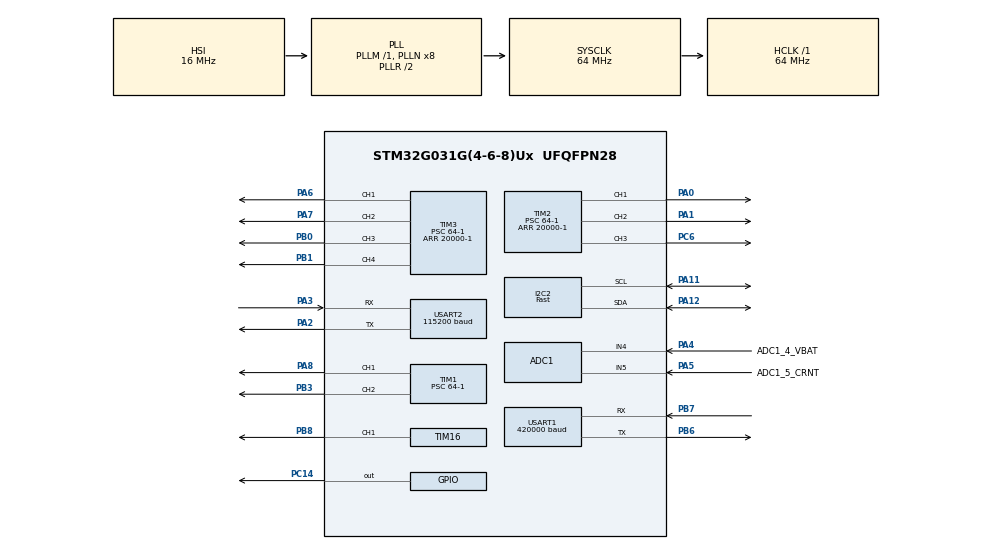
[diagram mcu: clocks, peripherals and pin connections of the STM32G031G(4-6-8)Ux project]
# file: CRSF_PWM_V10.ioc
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ADC1.Channel-4\#ChannelRegularConversion=ADC_CHANNEL_4
ADC1.Channel-5\#ChannelRegularConversion=ADC_CHANNEL_5
ADC1.ClockPrescaler=ADC_CLOCK_ASYNC_DIV128
ADC1.ContinuousConvMode=ENABLE
ADC1.DMAContinuousRequests=ENABLE
ADC1.DiscontinuousConvMode=DISABLE
ADC1.EOCSelection=ADC_EOC_SEQ_CONV
ADC1.LowPowerAutoPowerOff=DISABLE
ADC1.NbrOfConversion=2
ADC1.NbrOfConversionFlag=1
ADC1.Overrun=ADC_OVR_DATA_PRESERVED
ADC1.OversamplingMode=ENABLE
ADC1.Rank-4\#ChannelRegularConversion=1
ADC1.Rank-5\#ChannelRegularConversion=2
ADC1.Ratio=ADC_OVERSAMPLING_RATIO_16
ADC1.SamplingTime-4\#ChannelRegularConversion=ADC_SAMPLINGTIME_COMMON_1
ADC1.SamplingTime-5\#ChannelRegularConversion=ADC_SAMPLINGTIME_COMMON_1
ADC1.SamplingTimeCommon1=ADC_SAMPLETIME_160CYCLES_5
ADC1.SamplingTimeCommon2=ADC_SAMPLETIME_160CYCLES_5
ADC1.SelectedChannel=ADC_CHANNEL_4|ADC_CHANNEL_5|ADC_CHANNEL_VBAT
ADC1.Sequencer=FULLY_CONFIGURABLE
ADC1.master=1
Dma.ADC1.0.Direction=DMA_PERIPH_TO_MEMORY
Dma.ADC1.0.EventEnable=DISABLE
Dma.ADC1.0.Instance=DMA1_Channel1
Dma.ADC1.0.MemDataAlignment=DMA_MDATAALIGN_HALFWORD
Dma.ADC1.0.MemInc=DMA_MINC_ENABLE
Dma.ADC1.0.Mode=DMA_CIRCULAR
Dma.ADC1.0.PeriphDataAlignment=DMA_PDATAALIGN_HALFWORD
Dma.ADC1.0.PeriphInc=DMA_PINC_DISABLE
Dma.ADC1.0.Polarity=HAL_DMAMUX_REQ_GEN_RISING
Dma.ADC1.0.Priority=DMA_PRIORITY_LOW
Dma.ADC1.0.RequestNumber=1
Dma.ADC1.0.SignalID=NONE
Dma.ADC1.0.SyncEnable=DISABLE
Dma.ADC1.0.SyncPolarity=HAL_DMAMUX_SYNC_NO_EVENT
Dma.ADC1.0.SyncRequestNumber=1
Dma.ADC1.0.SyncSignalID=NONE
Dma.Request0=ADC1
I2C2.I2C_Speed_Mode=I2C_Fast
I2C2.Timing=0x00C12166
Mcu.Family=STM32G0
Mcu.Name=STM32G031G(4-6-8)Ux
Mcu.Package=UFQFPN28
NVIC.ADC1_IRQn=true\:0\:0\:false\:false\:true\:true\:true\:true
NVIC.DMA1_Channel1_IRQn=true\:0\:0\:false\:false\:true\:false\:true\:true
NVIC.I2C2_IRQn=true\:0\:0\:false\:false\:true\:true\:true\:true
NVIC.USART1_IRQn=true\:0\:0\:false\:false\:true\:true\:true\:true
NVIC.USART2_IRQn=true\:0\:0\:false\:false\:true\:true\:true\:true
PA0.Signal=S_TIM2_CH1_ETR
PA1.Signal=S_TIM2_CH2
PA11\ [PA9].GPIO_Pu=GPIO_PULLUP
PA11\ [PA9].Mode=I2C
PA11\ [PA9].Signal=I2C2_SCL
PA12\ [PA10].GPIO_Pu=GPIO_PULLUP
PA12\ [PA10].Mode=I2C
PA12\ [PA10].Signal=I2C2_SDA
PA13.Mode=Serial_Wire
PA13.Signal=SYS_SWDIO
PA14-BOOT0.Mode=Serial_Wire
PA14-BOOT0.Signal=SYS_SWCLK
PA2.Mode=Asynchronous
PA2.Signal=USART2_TX
PA3.GPIO_PuPd=GPIO_PULLUP
PA3.Mode=Asynchronous
PA3.Signal=USART2_RX
PA4.GPIO_Label=ADC1_4_VBAT
PA4.Mode=IN4
PA4.Signal=ADC1_IN4
PA5.GPIO_Label=ADC1_5_CRNT
PA5.Mode=IN5
PA5.Signal=ADC1_IN5
PA6.Signal=S_TIM3_CH1
PA7.Signal=S_TIM3_CH2
PA8.Signal=S_TIM1_CH1
PB0.Signal=S_TIM3_CH3
PB1.Signal=S_TIM3_CH4
PB3.Signal=S_TIM1_CH2
PB6.Mode=Asynchronous
PB6.Signal=USART1_TX
PB7.GPIO_PuPd=GPIO_PULLUP
PB7.Mode=Asynchronous
PB7.Signal=USART1_RX
PB8.Signal=S_TIM16_CH1
PC14-OSC32_IN\ (PC14).Signal=GPIO_Output
PC6.Signal=S_TIM2_CH3
ProjectManager.HeapSize=0x200
ProjectManager.StackSize=0x400
ProjectManager.TargetToolchain=CMake
RCC.ADCCLockSelection=RCC_ADCCLKSOURCE_PLLADC
RCC.ADCFreq_Value=32000000
RCC.AHBFreq_Value=64000000
RCC.CortexFreq_Value=64000000
RCC.EXTERNAL_CLOCK_VALUE=12288000
RCC.HCLKFreq_Value=64000000
RCC.HSE_VALUE=8000000
RCC.HSI_VALUE=16000000
RCC.LSE_VALUE=32768
RCC.PLLP=RCC_PLLP_DIV4
RCC.PLLQ=RCC_PLLQ_DIV4
RCC.SYSCLKFreq_VALUE=64000000
RCC.SYSCLKSource=RCC_SYSCLKSOURCE_PLLCLK
RCC.VCOOutputFreq_Value=128000000
SH.S_TIM16_CH1.0=TIM16_CH1,PWM Generation1 CH1
SH.S_TIM1_CH1.0=TIM1_CH1,PWM Generation1 CH1
SH.S_TIM1_CH2.0=TIM1_CH2,PWM Generation2 CH2
SH.S_TIM2_CH1_ETR.0=TIM2_CH1,PWM Generation1 CH1
SH.S_TIM2_CH2.0=TIM2_CH2,PWM Generation2 CH2
SH.S_TIM2_CH3.0=TIM2_CH3,PWM Generation3 CH3
SH.S_TIM3_CH1.0=TIM3_CH1,PWM Generation1 CH1
SH.S_TIM3_CH2.0=TIM3_CH2,PWM Generation2 CH2
SH.S_TIM3_CH3.0=TIM3_CH3,PWM Generation3 CH3
SH.S_TIM3_CH4.0=TIM3_CH4,PWM Generation4 CH4
TIM1.AutoReloadPreload=TIM_AUTORELOAD_PRELOAD_ENABLE
TIM1.Channel-PWM\ Generation1\ CH1=TIM_CHANNEL_1
TIM1.Channel-PWM\ Generation2\ CH2=TIM_CHANNEL_2
TIM1.OC1Preload_PWM=ENABLE
TIM1.OC2Preload_PWM=ENABLE
TIM1.Period=20000-1
TIM1.Prescaler=64-1
TIM16.AutoReloadPreload=TIM_AUTORELOAD_PRELOAD_ENABLE
TIM16.AutomaticOutput=TIM_AUTOMATICOUTPUT_DISABLE
TIM16.Channel=TIM_CHANNEL_1
TIM16.LockLevel=TIM_LOCKLEVEL_OFF
TIM16.OC1Preload_PWM=ENABLE
TIM16.OffStateIDLEMode=TIM_OSSI_DISABLE
TIM16.OffStateRunMode=TIM_OSSR_DISABLE
TIM16.Period=20000-1
TIM16.Prescaler=64-1
TIM16.Pulse=1500
TIM16.RepetitionCounter=0
TIM2.AutoReloadPreload=TIM_AUTORELOAD_PRELOAD_DISABLE
TIM2.Channel-PWM\ Generation1\ CH1=TIM_CHANNEL_1
TIM2.Channel-PWM\ Generation2\ CH2=TIM_CHANNEL_2
TIM2.Channel-PWM\ Generation3\ CH3=TIM_CHANNEL_3
TIM2.OC1Preload_PWM=ENABLE
TIM2.OC2Preload_PWM=ENABLE
TIM2.OC3Preload_PWM=ENABLE
TIM2.Period=20000-1
TIM2.Prescaler=64-1
TIM2.Pulse-PWM\ Generation1\ CH1=1500
TIM2.Pulse-PWM\ Generation2\ CH2=1500
TIM2.Pulse-PWM\ Generation3\ CH3=1500
TIM3.AutoReloadPreload=TIM_AUTORELOAD_PRELOAD_ENABLE
TIM3.Channel-PWM\ Generation1\ CH1=TIM_CHANNEL_1
TIM3.Channel-PWM\ Generation2\ CH2=TIM_CHANNEL_2
TIM3.Channel-PWM\ Generation3\ CH3=TIM_CHANNEL_3
TIM3.Channel-PWM\ Generation4\ CH4=TIM_CHANNEL_4
TIM3.OC1Preload_PWM=ENABLE
TIM3.OC2Preload_PWM=ENABLE
TIM3.OC3Preload_PWM=ENABLE
TIM3.OC4Preload_PWM=ENABLE
TIM3.Period=20000-1
TIM3.Prescaler=64-1
USART1.BaudRate=420000
USART1.DMADisableonRxErrorParam=ADVFEATURE_DMA_DISABLEONRXERROR
USART1.VirtualMode-Asynchronous=VM_ASYNC
USART2.BaudRate=115200
USART2.VirtualMode-Asynchronous=VM_ASYNC
VP_ADC1_Vbat_Input.Mode=IN-Vbat
VP_TIM16_VS_ClockSourceINT.Mode=Enable_Timer
VP_TIM1_VS_ClockSourceINT.Mode=Internal
VP_TIM2_VS_ClockSourceINT.Mode=Internal
VP_TIM3_VS_ClockSourceINT.Mode=Internal
board=custom

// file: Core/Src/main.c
/* USER CODE BEGIN Header */
/**
  ******************************************************************************
  * @file           : main.c
  * @brief          : Main program body
  ******************************************************************************
  * @attention
  *
  * Copyright (c) 2026 STMicroelectronics.
  * All rights reserved.
  *
  * This software is licensed under terms that can be found in the LICENSE file
  * in the root directory of this software component.
  * If no LICENSE file comes with this software, it is provided AS-IS.
  *
  ******************************************************************************
  */
/* USER CODE END Header */
#include "main.h"

/* USER CODE BEGIN Includes */
#include <stdio.h>
#include "../inc/user_main.h"
#include "stm32g0xx_hal_uart.h"
/* USER CODE END Includes */

/* USER CODE BEGIN PD */
/* moved to user_main.h */
/* USER CODE END PD */

ADC_HandleTypeDef hadc1;
DMA_HandleTypeDef hdma_adc1;

I2C_HandleTypeDef hi2c2;

TIM_HandleTypeDef htim1;
TIM_HandleTypeDef htim2;
TIM_HandleTypeDef htim3;
TIM_HandleTypeDef htim16;

UART_HandleTypeDef huart1;
UART_HandleTypeDef huart2;

void SystemClock_Config(void);
static void MX_GPIO_Init(void);
static void MX_DMA_Init(void);
static void MX_ADC1_Init(void);
static void MX_I2C2_Init(void);
static void MX_TIM1_Init(void);
static void MX_TIM2_Init(void);
static void MX_TIM3_Init(void);
static void MX_TIM16_Init(void);
static void MX_USART1_UART_Init(void);
static void MX_USART2_UART_Init(void);
/* USER CODE BEGIN PFP */
/* moved to user_main.h */
/* USER CODE END PFP */

int main(void)
{

  /* MCU Configuration--------------------------------------------------------*/

  /* Reset of all peripherals, Initializes the Flash interface and the Systick. */
  HAL_Init();

  /* Configure the system clock */
  SystemClock_Config();

  /* Initialize all configured peripherals */
  MX_GPIO_Init();
  MX_DMA_Init();
  MX_ADC1_Init();
  MX_I2C2_Init();
  MX_TIM1_Init();
  MX_TIM2_Init();
  MX_TIM3_Init();
  MX_TIM16_Init();
  MX_USART1_UART_Init();
  MX_USART2_UART_Init();
  /* USER CODE BEGIN 2 */
  user_init();
  /* USER CODE END 2 */

  /* Infinite loop */
  /* USER CODE BEGIN WHILE */
  while (1)
  {
    user_loop_step();
#ifdef USER_LOOP
#endif
    /* USER CODE END WHILE */

  }
}

void SystemClock_Config(void)
{
  RCC_OscInitTypeDef RCC_OscInitStruct = {0};
  RCC_ClkInitTypeDef RCC_ClkInitStruct = {0};

  /** Configure the main internal regulator output voltage
  */
  HAL_PWREx_ControlVoltageScaling(PWR_REGULATOR_VOLTAGE_SCALE1);

  /** Initializes the RCC Oscillators according to the specified parameters
  * in the RCC_OscInitTypeDef structure.
  */
  RCC_OscInitStruct.OscillatorType = RCC_OSCILLATORTYPE_HSI;
  RCC_OscInitStruct.HSIState = RCC_HSI_ON;
  RCC_OscInitStruct.HSIDiv = RCC_HSI_DIV1;
  RCC_OscInitStruct.HSICalibrationValue = RCC_HSICALIBRATION_DEFAULT;
  RCC_OscInitStruct.PLL.PLLState = RCC_PLL_ON;
  RCC_OscInitStruct.PLL.PLLSource = RCC_PLLSOURCE_HSI;
  RCC_OscInitStruct.PLL.PLLM = RCC_PLLM_DIV1;
  RCC_OscInitStruct.PLL.PLLN = 8;
  RCC_OscInitStruct.PLL.PLLP = RCC_PLLP_DIV4;
  RCC_OscInitStruct.PLL.PLLQ = RCC_PLLQ_DIV4;
  RCC_OscInitStruct.PLL.PLLR = RCC_PLLR_DIV2;
  if (HAL_RCC_OscConfig(&RCC_OscInitStruct) != HAL_OK)
  {
    Error_Handler();
  }

  /** Initializes the CPU, AHB and APB buses clocks
  */
  RCC_ClkInitStruct.ClockType = RCC_CLOCKTYPE_HCLK|RCC_CLOCKTYPE_SYSCLK
                              |RCC_CLOCKTYPE_PCLK1;
  RCC_ClkInitStruct.SYSCLKSource = RCC_SYSCLKSOURCE_PLLCLK;
  RCC_ClkInitStruct.AHBCLKDivider = RCC_SYSCLK_DIV1;
  RCC_ClkInitStruct.APB1CLKDivider = RCC_HCLK_DIV1;

  if (HAL_RCC_ClockConfig(&RCC_ClkInitStruct, FLASH_LATENCY_2) != HAL_OK)
  {
    Error_Handler();
  }
}

static void MX_ADC1_Init(void)
{

  ADC_ChannelConfTypeDef sConfig = {0};

  /** Configure the global features of the ADC (Clock, Resolution, Data Alignment and number of conversion)
  */
  hadc1.Instance = ADC1;
  hadc1.Init.ClockPrescaler = ADC_CLOCK_ASYNC_DIV128;
  hadc1.Init.Resolution = ADC_RESOLUTION_12B;
  hadc1.Init.DataAlign = ADC_DATAALIGN_RIGHT;
  hadc1.Init.ScanConvMode = ADC_SCAN_ENABLE;
  hadc1.Init.EOCSelection = ADC_EOC_SEQ_CONV;
  hadc1.Init.LowPowerAutoWait = DISABLE;
  hadc1.Init.LowPowerAutoPowerOff = DISABLE;
  hadc1.Init.ContinuousConvMode = ENABLE;
  hadc1.Init.NbrOfConversion = 2;
  hadc1.Init.DiscontinuousConvMode = DISABLE;
  hadc1.Init.ExternalTrigConv = ADC_SOFTWARE_START;
  hadc1.Init.ExternalTrigConvEdge = ADC_EXTERNALTRIGCONVEDGE_NONE;
  hadc1.Init.DMAContinuousRequests = ENABLE;
  hadc1.Init.Overrun = ADC_OVR_DATA_PRESERVED;
  hadc1.Init.SamplingTimeCommon1 = ADC_SAMPLETIME_160CYCLES_5;
  hadc1.Init.SamplingTimeCommon2 = ADC_SAMPLETIME_160CYCLES_5;
  hadc1.Init.OversamplingMode = ENABLE;
  hadc1.Init.Oversampling.Ratio = ADC_OVERSAMPLING_RATIO_16;
  hadc1.Init.Oversampling.RightBitShift = ADC_RIGHTBITSHIFT_NONE;
  hadc1.Init.Oversampling.TriggeredMode = ADC_TRIGGEREDMODE_SINGLE_TRIGGER;
  hadc1.Init.TriggerFrequencyMode = ADC_TRIGGER_FREQ_HIGH;
  if (HAL_ADC_Init(&hadc1) != HAL_OK)
  {
    Error_Handler();
  }

  /** Configure Regular Channel
  */
  sConfig.Channel = ADC_CHANNEL_4;
  sConfig.Rank = ADC_REGULAR_RANK_1;
  sConfig.SamplingTime = ADC_SAMPLINGTIME_COMMON_1;
  if (HAL_ADC_ConfigChannel(&hadc1, &sConfig) != HAL_OK)
  {
    Error_Handler();
  }

  /** Configure Regular Channel
  */
  sConfig.Channel = ADC_CHANNEL_5;
  sConfig.Rank = ADC_REGULAR_RANK_2;
  if (HAL_ADC_ConfigChannel(&hadc1, &sConfig) != HAL_OK)
  {
    Error_Handler();
  }

}

static void MX_I2C2_Init(void)
{

  hi2c2.Instance = I2C2;
  hi2c2.Init.Timing = 0x00C12166;
  hi2c2.Init.OwnAddress1 = 0;
  hi2c2.Init.AddressingMode = I2C_ADDRESSINGMODE_7BIT;
  hi2c2.Init.DualAddressMode = I2C_DUALADDRESS_DISABLE;
  hi2c2.Init.OwnAddress2 = 0;
  hi2c2.Init.OwnAddress2Masks = I2C_OA2_NOMASK;
  hi2c2.Init.GeneralCallMode = I2C_GENERALCALL_DISABLE;
  hi2c2.Init.NoStretchMode = I2C_NOSTRETCH_DISABLE;
  if (HAL_I2C_Init(&hi2c2) != HAL_OK)
  {
    Error_Handler();
  }

  /** Configure Analogue filter
  */
  if (HAL_I2CEx_ConfigAnalogFilter(&hi2c2, I2C_ANALOGFILTER_ENABLE) != HAL_OK)
  {
    Error_Handler();
  }

  /** Configure Digital filter
  */
  if (HAL_I2CEx_ConfigDigitalFilter(&hi2c2, 0) != HAL_OK)
  {
    Error_Handler();
  }

}

static void MX_TIM1_Init(void)
{

  TIM_ClockConfigTypeDef sClockSourceConfig = {0};
  TIM_MasterConfigTypeDef sMasterConfig = {0};
  TIM_OC_InitTypeDef sConfigOC = {0};
  TIM_BreakDeadTimeConfigTypeDef sBreakDeadTimeConfig = {0};

  htim1.Instance = TIM1;
  htim1.Init.Prescaler = 64-1;
  htim1.Init.CounterMode = TIM_COUNTERMODE_UP;
  htim1.Init.Period = 20000-1;
  htim1.Init.ClockDivision = TIM_CLOCKDIVISION_DIV1;
  htim1.Init.RepetitionCounter = 0;
  htim1.Init.AutoReloadPreload = TIM_AUTORELOAD_PRELOAD_ENABLE;
  if (HAL_TIM_Base_Init(&htim1) != HAL_OK)
  {
    Error_Handler();
  }
  sClockSourceConfig.ClockSource = TIM_CLOCKSOURCE_INTERNAL;
  if (HAL_TIM_ConfigClockSource(&htim1, &sClockSourceConfig) != HAL_OK)
  {
    Error_Handler();
  }
  if (HAL_TIM_PWM_Init(&htim1) != HAL_OK)
  {
    Error_Handler();
  }
  sMasterConfig.MasterOutputTrigger = TIM_TRGO_RESET;
  sMasterConfig.MasterOutputTrigger2 = TIM_TRGO2_RESET;
  sMasterConfig.MasterSlaveMode = TIM_MASTERSLAVEMODE_DISABLE;
  if (HAL_TIMEx_MasterConfigSynchronization(&htim1, &sMasterConfig) != HAL_OK)
  {
    Error_Handler();
  }
  sConfigOC.OCMode = TIM_OCMODE_PWM1;
  sConfigOC.Pulse = 0;
  sConfigOC.OCPolarity = TIM_OCPOLARITY_HIGH;
  sConfigOC.OCNPolarity = TIM_OCNPOLARITY_HIGH;
  sConfigOC.OCFastMode = TIM_OCFAST_DISABLE;
  sConfigOC.OCIdleState = TIM_OCIDLESTATE_RESET;
  sConfigOC.OCNIdleState = TIM_OCNIDLESTATE_RESET;
  if (HAL_TIM_PWM_ConfigChannel(&htim1, &sConfigOC, TIM_CHANNEL_1) != HAL_OK)
  {
    Error_Handler();
  }
  if (HAL_TIM_PWM_ConfigChannel(&htim1, &sConfigOC, TIM_CHANNEL_2) != HAL_OK)
  {
    Error_Handler();
  }
  sBreakDeadTimeConfig.OffStateRunMode = TIM_OSSR_DISABLE;
  sBreakDeadTimeConfig.OffStateIDLEMode = TIM_OSSI_DISABLE;
  sBreakDeadTimeConfig.LockLevel = TIM_LOCKLEVEL_OFF;
  sBreakDeadTimeConfig.DeadTime = 0;
  sBreakDeadTimeConfig.BreakState = TIM_BREAK_DISABLE;
  sBreakDeadTimeConfig.BreakPolarity = TIM_BREAKPOLARITY_HIGH;
  sBreakDeadTimeConfig.BreakFilter = 0;
  sBreakDeadTimeConfig.BreakAFMode = TIM_BREAK_AFMODE_INPUT;
  sBreakDeadTimeConfig.Break2State = TIM_BREAK2_DISABLE;
  sBreakDeadTimeConfig.Break2Polarity = TIM_BREAK2POLARITY_HIGH;
  sBreakDeadTimeConfig.Break2Filter = 0;
  sBreakDeadTimeConfig.Break2AFMode = TIM_BREAK_AFMODE_INPUT;
  sBreakDeadTimeConfig.AutomaticOutput = TIM_AUTOMATICOUTPUT_DISABLE;
  if (HAL_TIMEx_ConfigBreakDeadTime(&htim1, &sBreakDeadTimeConfig) != HAL_OK)
  {
    Error_Handler();
  }
  HAL_TIM_MspPostInit(&htim1);

}

static void MX_TIM2_Init(void)
{

  TIM_ClockConfigTypeDef sClockSourceConfig = {0};
  TIM_MasterConfigTypeDef sMasterConfig = {0};
  TIM_OC_InitTypeDef sConfigOC = {0};

  htim2.Instance = TIM2;
  htim2.Init.Prescaler = 64-1;
  htim2.Init.CounterMode = TIM_COUNTERMODE_UP;
  htim2.Init.Period = 20000-1;
  htim2.Init.ClockDivision = TIM_CLOCKDIVISION_DIV1;
  htim2.Init.AutoReloadPreload = TIM_AUTORELOAD_PRELOAD_DISABLE;
  if (HAL_TIM_Base_Init(&htim2) != HAL_OK)
  {
    Error_Handler();
  }
  sClockSourceConfig.ClockSource = TIM_CLOCKSOURCE_INTERNAL;
  if (HAL_TIM_ConfigClockSource(&htim2, &sClockSourceConfig) != HAL_OK)
  {
    Error_Handler();
  }
  if (HAL_TIM_PWM_Init(&htim2) != HAL_OK)
  {
    Error_Handler();
  }
  sMasterConfig.MasterOutputTrigger = TIM_TRGO_RESET;
  sMasterConfig.MasterSlaveMode = TIM_MASTERSLAVEMODE_DISABLE;
  if (HAL_TIMEx_MasterConfigSynchronization(&htim2, &sMasterConfig) != HAL_OK)
  {
    Error_Handler();
  }
  sConfigOC.OCMode = TIM_OCMODE_PWM1;
  sConfigOC.Pulse = 1500;
  sConfigOC.OCPolarity = TIM_OCPOLARITY_HIGH;
  sConfigOC.OCFastMode = TIM_OCFAST_DISABLE;
  if (HAL_TIM_PWM_ConfigChannel(&htim2, &sConfigOC, TIM_CHANNEL_1) != HAL_OK)
  {
    Error_Handler();
  }
  if (HAL_TIM_PWM_ConfigChannel(&htim2, &sConfigOC, TIM_CHANNEL_2) != HAL_OK)
  {
    Error_Handler();
  }
  if (HAL_TIM_PWM_ConfigChannel(&htim2, &sConfigOC, TIM_CHANNEL_3) != HAL_OK)
  {
    Error_Handler();
  }
  HAL_TIM_MspPostInit(&htim2);

}

static void MX_TIM3_Init(void)
{

  TIM_ClockConfigTypeDef sClockSourceConfig = {0};
  TIM_MasterConfigTypeDef sMasterConfig = {0};
  TIM_OC_InitTypeDef sConfigOC = {0};

  htim3.Instance = TIM3;
  htim3.Init.Prescaler = 64-1;
  htim3.Init.CounterMode = TIM_COUNTERMODE_UP;
  htim3.Init.Period = 20000-1;
  htim3.Init.ClockDivision = TIM_CLOCKDIVISION_DIV1;
  htim3.Init.AutoReloadPreload = TIM_AUTORELOAD_PRELOAD_ENABLE;
  if (HAL_TIM_Base_Init(&htim3) != HAL_OK)
  {
    Error_Handler();
  }
  sClockSourceConfig.ClockSource = TIM_CLOCKSOURCE_INTERNAL;
  if (HAL_TIM_ConfigClockSource(&htim3, &sClockSourceConfig) != HAL_OK)
  {
    Error_Handler();
  }
  if (HAL_TIM_PWM_Init(&htim3) != HAL_OK)
  {
    Error_Handler();
  }
  sMasterConfig.MasterOutputTrigger = TIM_TRGO_RESET;
  sMasterConfig.MasterSlaveMode = TIM_MASTERSLAVEMODE_DISABLE;
  if (HAL_TIMEx_MasterConfigSynchronization(&htim3, &sMasterConfig) != HAL_OK)
  {
    Error_Handler();
  }
  sConfigOC.OCMode = TIM_OCMODE_PWM1;
  sConfigOC.Pulse = 0;
  sConfigOC.OCPolarity = TIM_OCPOLARITY_HIGH;
  sConfigOC.OCFastMode = TIM_OCFAST_DISABLE;
  if (HAL_TIM_PWM_ConfigChannel(&htim3, &sConfigOC, TIM_CHANNEL_1) != HAL_OK)
  {
    Error_Handler();
  }
  if (HAL_TIM_PWM_ConfigChannel(&htim3, &sConfigOC, TIM_CHANNEL_2) != HAL_OK)
  {
    Error_Handler();
  }
  if (HAL_TIM_PWM_ConfigChannel(&htim3, &sConfigOC, TIM_CHANNEL_3) != HAL_OK)
  {
    Error_Handler();
  }
  if (HAL_TIM_PWM_ConfigChannel(&htim3, &sConfigOC, TIM_CHANNEL_4) != HAL_OK)
  {
    Error_Handler();
  }
  HAL_TIM_MspPostInit(&htim3);

}

static void MX_TIM16_Init(void)
{

  TIM_OC_InitTypeDef sConfigOC = {0};
  TIM_BreakDeadTimeConfigTypeDef sBreakDeadTimeConfig = {0};

  htim16.Instance = TIM16;
  htim16.Init.Prescaler = 64-1;
  htim16.Init.CounterMode = TIM_COUNTERMODE_UP;
  htim16.Init.Period = 20000-1;
  htim16.Init.ClockDivision = TIM_CLOCKDIVISION_DIV1;
  htim16.Init.RepetitionCounter = 0;
  htim16.Init.AutoReloadPreload = TIM_AUTORELOAD_PRELOAD_ENABLE;
  if (HAL_TIM_Base_Init(&htim16) != HAL_OK)
  {
    Error_Handler();
  }
  if (HAL_TIM_PWM_Init(&htim16) != HAL_OK)
  {
    Error_Handler();
  }
  sConfigOC.OCMode = TIM_OCMODE_PWM1;
  sConfigOC.Pulse = 1500;
  sConfigOC.OCPolarity = TIM_OCPOLARITY_HIGH;
  sConfigOC.OCNPolarity = TIM_OCNPOLARITY_HIGH;
  sConfigOC.OCFastMode = TIM_OCFAST_DISABLE;
  sConfigOC.OCIdleState = TIM_OCIDLESTATE_RESET;
  sConfigOC.OCNIdleState = TIM_OCNIDLESTATE_RESET;
  if (HAL_TIM_PWM_ConfigChannel(&htim16, &sConfigOC, TIM_CHANNEL_1) != HAL_OK)
  {
    Error_Handler();
  }
  sBreakDeadTimeConfig.OffStateRunMode = TIM_OSSR_DISABLE;
  sBreakDeadTimeConfig.OffStateIDLEMode = TIM_OSSI_DISABLE;
  sBreakDeadTimeConfig.LockLevel = TIM_LOCKLEVEL_OFF;
  sBreakDeadTimeConfig.DeadTime = 0;
  sBreakDeadTimeConfig.BreakState = TIM_BREAK_DISABLE;
  sBreakDeadTimeConfig.BreakPolarity = TIM_BREAKPOLARITY_HIGH;
  sBreakDeadTimeConfig.BreakFilter = 0;
  sBreakDeadTimeConfig.AutomaticOutput = TIM_AUTOMATICOUTPUT_DISABLE;
  if (HAL_TIMEx_ConfigBreakDeadTime(&htim16, &sBreakDeadTimeConfig) != HAL_OK)
  {
    Error_Handler();
  }
  HAL_TIM_MspPostInit(&htim16);

}

static void MX_USART1_UART_Init(void)
{

  huart1.Instance = USART1;
  huart1.Init.BaudRate = 420000;
  huart1.Init.WordLength = UART_WORDLENGTH_8B;
  huart1.Init.StopBits = UART_STOPBITS_1;
  huart1.Init.Parity = UART_PARITY_NONE;
  huart1.Init.Mode = UART_MODE_TX_RX;
  huart1.Init.HwFlowCtl = UART_HWCONTROL_NONE;
  huart1.Init.OverSampling = UART_OVERSAMPLING_16;
  huart1.Init.OneBitSampling = UART_ONE_BIT_SAMPLE_DISABLE;
  huart1.Init.ClockPrescaler = UART_PRESCALER_DIV1;
  huart1.AdvancedInit.AdvFeatureInit = UART_ADVFEATURE_DMADISABLEONERROR_INIT;
  huart1.AdvancedInit.DMADisableonRxError = UART_ADVFEATURE_DMA_DISABLEONRXERROR;
  if (HAL_UART_Init(&huart1) != HAL_OK)
  {
    Error_Handler();
  }
  if (HAL_UARTEx_SetTxFifoThreshold(&huart1, UART_TXFIFO_THRESHOLD_1_8) != HAL_OK)
  {
    Error_Handler();
  }
  if (HAL_UARTEx_SetRxFifoThreshold(&huart1, UART_RXFIFO_THRESHOLD_1_8) != HAL_OK)
  {
    Error_Handler();
  }
  if (HAL_UARTEx_DisableFifoMode(&huart1) != HAL_OK)
  {
    Error_Handler();
  }

}

static void MX_USART2_UART_Init(void)
{

  huart2.Instance = USART2;
  huart2.Init.BaudRate = 115200;
  huart2.Init.WordLength = UART_WORDLENGTH_8B;
  huart2.Init.StopBits = UART_STOPBITS_1;
  huart2.Init.Parity = UART_PARITY_NONE;
  huart2.Init.Mode = UART_MODE_TX_RX;
  huart2.Init.HwFlowCtl = UART_HWCONTROL_NONE;
  huart2.Init.OverSampling = UART_OVERSAMPLING_16;
  huart2.Init.OneBitSampling = UART_ONE_BIT_SAMPLE_DISABLE;
  huart2.Init.ClockPrescaler = UART_PRESCALER_DIV1;
  huart2.AdvancedInit.AdvFeatureInit = UART_ADVFEATURE_NO_INIT;
  if (HAL_UART_Init(&huart2) != HAL_OK)
  {
    Error_Handler();
  }

}

static void MX_DMA_Init(void)
{

  /* DMA controller clock enable */
  __HAL_RCC_DMA1_CLK_ENABLE();

  /* DMA interrupt init */
  /* DMA1_Channel1_IRQn interrupt configuration */
  HAL_NVIC_SetPriority(DMA1_Channel1_IRQn, 0, 0);
  HAL_NVIC_EnableIRQ(DMA1_Channel1_IRQn);

}

static void MX_GPIO_Init(void)
{
  GPIO_InitTypeDef GPIO_InitStruct = {0};

  /* GPIO Ports Clock Enable */
  __HAL_RCC_GPIOC_CLK_ENABLE();
  __HAL_RCC_GPIOA_CLK_ENABLE();
  __HAL_RCC_GPIOB_CLK_ENABLE();

  /*Configure GPIO pin Output Level */
  HAL_GPIO_WritePin(GPIOC, GPIO_PIN_14, GPIO_PIN_RESET);

  /*Configure GPIO pin : PC14 */
  GPIO_InitStruct.Pin = GPIO_PIN_14;
  GPIO_InitStruct.Mode = GPIO_MODE_OUTPUT_PP;
  GPIO_InitStruct.Pull = GPIO_NOPULL;
  GPIO_InitStruct.Speed = GPIO_SPEED_FREQ_LOW;
  HAL_GPIO_Init(GPIOC, &GPIO_InitStruct);

  /* USER CODE BEGIN MX_GPIO_Init_2 */
/*  GPIO_InitStruct.Pin = GPIO_PIN_8;
  GPIO_InitStruct.Mode = GPIO_MODE_AF_PP;
  GPIO_InitStruct.Pull = GPIO_NOPULL;
  GPIO_InitStruct.Speed = GPIO_SPEED_FREQ_LOW;
  GPIO_InitStruct.Alternate = GPIO_AF2_TIM1; // Ensure this matches TIM1_CH1 for G0
  HAL_GPIO_Init(GPIOA, &GPIO_InitStruct);
*/
  /* USER CODE END MX_GPIO_Init_2 */
}

void Error_Handler(void)
{
  /* USER CODE BEGIN Error_Handler_Debug */
  /* User can add his own implementation to report the HAL error return state */
  char MSG[20];

  __disable_irq();
       sprintf(MSG, "Error \r\n");
      HAL_UART_Transmit(&huart2, (const uint8_t *) MSG, sizeof(MSG), 100);
  while (1)
  {
  }
  /* USER CODE END Error_Handler_Debug */
}
